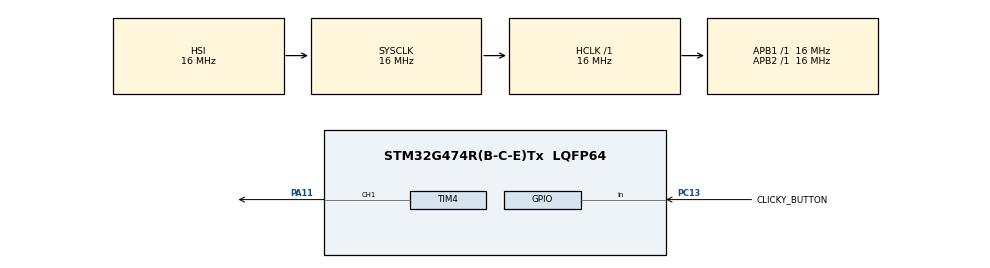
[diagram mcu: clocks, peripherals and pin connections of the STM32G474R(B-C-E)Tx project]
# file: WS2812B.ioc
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Dma.Request0=TIM4_CH1
Dma.TIM4_CH1.0.Direction=DMA_PERIPH_TO_MEMORY
Dma.TIM4_CH1.0.EventEnable=DISABLE
Dma.TIM4_CH1.0.Instance=DMA1_Channel1
Dma.TIM4_CH1.0.MemDataAlignment=DMA_MDATAALIGN_BYTE
Dma.TIM4_CH1.0.MemInc=DMA_MINC_ENABLE
Dma.TIM4_CH1.0.Mode=DMA_NORMAL
Dma.TIM4_CH1.0.PeriphDataAlignment=DMA_PDATAALIGN_HALFWORD
Dma.TIM4_CH1.0.PeriphInc=DMA_PINC_DISABLE
Dma.TIM4_CH1.0.Polarity=HAL_DMAMUX_REQ_GEN_RISING
Dma.TIM4_CH1.0.Priority=DMA_PRIORITY_LOW
Dma.TIM4_CH1.0.RequestNumber=1
Dma.TIM4_CH1.0.SignalID=NONE
Dma.TIM4_CH1.0.SyncEnable=DISABLE
Dma.TIM4_CH1.0.SyncPolarity=HAL_DMAMUX_SYNC_NO_EVENT
Dma.TIM4_CH1.0.SyncRequestNumber=1
Dma.TIM4_CH1.0.SyncSignalID=NONE
Mcu.Family=STM32G4
Mcu.Name=STM32G474R(B-C-E)Tx
Mcu.Package=LQFP64
NVIC.DMA1_Channel1_IRQn=true\:0\:0\:false\:false\:true\:false\:true\:true
NVIC.PriorityGroup=NVIC_PRIORITYGROUP_4
PA11.Signal=S_TIM4_CH1
PC13.GPIO_Label=CLICKY_BUTTON
PC13.Signal=GPIO_Input
ProjectManager.HeapSize=0x200
ProjectManager.StackSize=0x400
ProjectManager.TargetToolchain=STM32CubeIDE
RCC.AHBFreq_Value=16000000
RCC.APB1Freq_Value=16000000
RCC.APB1TimFreq_Value=16000000
RCC.APB2Freq_Value=16000000
RCC.APB2TimFreq_Value=16000000
RCC.CortexFreq_Value=16000000
RCC.EXTERNAL_CLOCK_VALUE=12288000
RCC.HCLKFreq_Value=16000000
RCC.HSE_VALUE=8000000
RCC.HSI48_VALUE=48000000
RCC.HSI_VALUE=16000000
RCC.LSE_VALUE=32768
RCC.SYSCLKFreq_VALUE=16000000
RCC.USBFreq_Value=64000000
RCC.VCOOutputFreq_Value=128000000
SH.S_TIM4_CH1.0=TIM4_CH1,PWM Generation1 CH1
TIM4.Channel-PWM\ Generation1\ CH1=TIM_CHANNEL_1
TIM4.PeriodNoDither=20
TIM4.Prescaler=0
TIM4.PulseNoDither_1=0
VP_SYS_VS_DBSignals.Mode=DisableDeadBatterySignals
board=custom

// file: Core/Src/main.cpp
/* USER CODE BEGIN Header */
/**
  ******************************************************************************
  * @file           : main.c
  * @brief          : Main program body
  ******************************************************************************
  * @attention
  *
  * Copyright (c) 2024 STMicroelectronics.
  * All rights reserved.
  *
  * This software is licensed under terms that can be found in the LICENSE file
  * in the root directory of this software component.
  * If no LICENSE file comes with this software, it is provided AS-IS.
  *
  ******************************************************************************
  */
/* USER CODE END Header */
#include "main.h"

/* USER CODE BEGIN Includes */
#include "WS2812B.hpp"

/* USER CODE END Includes */

TIM_HandleTypeDef htim4;
DMA_HandleTypeDef hdma_tim4_ch1;

void SystemClock_Config(void);
static void MX_GPIO_Init(void);
static void MX_DMA_Init(void);
static void MX_TIM4_Init(void);

/* USER CODE BEGIN 0 */
#define PERIOD_MS 3000
// Percentage of current period. 0% - 0, 100% - 255
uint8_t area = 0;
// Stores time to calculate percentage.
uint32_t last_time;
// 1 if button has been pressed and hasn't been cleared yet.
uint8_t clicked = 0;

/**
 * Checks if GPIO has been shorted.
 *
 * 255 is end of the period.
 * 0 is start of the period.
 * May miss timings when GPIO is pressed if full execution of main loop takes too long.
 * A better solution would be to use interrupts, but this simple example will do.
 */
#warning "Use interrupts instead if main loop runs too long to catch all presses"
void update_click(GPIO_TypeDef *GPIOx, uint16_t GPIO_Pin){
	if(HAL_GPIO_ReadPin(GPIOx, GPIO_Pin)) clicked = 1;
	else clicked = 0;
}

/**
 * Updates the percentage of the current period.
 *
 * 255 is end of the period.
 * 0 is start of the period.
 */
void update_area(){
	uint32_t current_time = HAL_GetTick();
	if(current_time - last_time >= PERIOD_MS){
		last_time=current_time;
		area = 0;
	}
	// I know it will be only approximation and for small values of delta T it will be shown as 0 but it's good enough
	area = ((current_time-last_time)*255)/PERIOD_MS;
}

/**
 * Modulation of the green part of the LED.
 *
 * Generates a pulse with a sawtooth signal.
 */
uint8_t greenStep(uint8_t area){
	return area;
}

/**
 * Modulation of the red part of the LED.
 *
 * Generates a pulse with a width of 1/2 the period.
 */
uint8_t redStep(uint8_t area){
	if(area < 128) return 255;
	return 0;
}

/**
 * Modulation of the blue part of the LED.
 *
 * Blinks 3 in the period after registering clicked GPIO.
 */
uint8_t blueStep(uint8_t area, uint8_t clicked){
	if(!clicked) return 0;

	// some approximation, because it doesn't have to be that precise
	else{
		if(((area - (area % 42))/43) & 1) return 255;
	}
	return 0;
}

/**
 * LED modulation function.
 *
 * Modulates LEDs in the strip to output the correct signals.
 */
int modulation(LED* led, const int i, const int feedback){
	led->blue = blueStep(area, clicked);
	led->red = redStep(area);
	led->red = redStep(area);
	return 0;
}

/**
 * PWM completion callback.
 *
 * Called after the PWM function has been executed, tells PWM to stop before the next batch of data.
 */
void HAL_TIM_PWM_PulseFinishedCallback(TIM_HandleTypeDef *htim)
{
	if(TIM4 == htim->Instance)
	{
		HAL_TIM_PWM_Stop(&htim4, TIM_CHANNEL_1);
	}
}

/* USER CODE END 0 */

int main(void)
{

  /* MCU Configuration--------------------------------------------------------*/

  /* Reset of all peripherals, Initializes the Flash interface and the Systick. */
  HAL_Init();

  /* Configure the system clock */
  SystemClock_Config();

  /* Initialize all configured peripherals */
  MX_GPIO_Init();
  MX_DMA_Init();
  MX_TIM4_Init();
  /* USER CODE BEGIN 2 */
  // Set start time to ensure there is no garbage in the variable.
  last_time = HAL_GetTick();
  // Set starting percentage to 0
  area = 0;
  // Initialise the strip with the length of the 10 (10 LEDs).
  Strip<10>	strip(&htim4, TIM_CHANNEL_1);
  // Set callback for LED.
  strip.setLedCallback(modulation);
  /* USER CODE END 2 */

  /* Infinite loop */
  /* USER CODE BEGIN WHILE */
  while (1)
  {
	// Check for presses.
	update_click(CLICKY_BUTTON_GPIO_Port, CLICKY_BUTTON_Pin);
	// Update period.
	update_area();
	// Run strip
    strip.run();
    /* USER CODE END WHILE */

  }
}

void SystemClock_Config(void)
{
  RCC_OscInitTypeDef RCC_OscInitStruct = {0};
  RCC_ClkInitTypeDef RCC_ClkInitStruct = {0};

  /** Configure the main internal regulator output voltage
  */
  HAL_PWREx_ControlVoltageScaling(PWR_REGULATOR_VOLTAGE_SCALE1);

  /** Initializes the RCC Oscillators according to the specified parameters
  * in the RCC_OscInitTypeDef structure.
  */
  RCC_OscInitStruct.OscillatorType = RCC_OSCILLATORTYPE_HSI;
  RCC_OscInitStruct.HSIState = RCC_HSI_ON;
  RCC_OscInitStruct.HSICalibrationValue = RCC_HSICALIBRATION_DEFAULT;
  RCC_OscInitStruct.PLL.PLLState = RCC_PLL_NONE;
  if (HAL_RCC_OscConfig(&RCC_OscInitStruct) != HAL_OK)
  {
    Error_Handler();
  }

  /** Initializes the CPU, AHB and APB buses clocks
  */
  RCC_ClkInitStruct.ClockType = RCC_CLOCKTYPE_HCLK|RCC_CLOCKTYPE_SYSCLK
                              |RCC_CLOCKTYPE_PCLK1|RCC_CLOCKTYPE_PCLK2;
  RCC_ClkInitStruct.SYSCLKSource = RCC_SYSCLKSOURCE_HSI;
  RCC_ClkInitStruct.AHBCLKDivider = RCC_SYSCLK_DIV1;
  RCC_ClkInitStruct.APB1CLKDivider = RCC_HCLK_DIV1;
  RCC_ClkInitStruct.APB2CLKDivider = RCC_HCLK_DIV1;

  if (HAL_RCC_ClockConfig(&RCC_ClkInitStruct, FLASH_LATENCY_0) != HAL_OK)
  {
    Error_Handler();
  }
}

static void MX_TIM4_Init(void)
{

  TIM_MasterConfigTypeDef sMasterConfig = {0};
  TIM_OC_InitTypeDef sConfigOC = {0};

  htim4.Instance = TIM4;
  htim4.Init.Prescaler = 0;
  htim4.Init.CounterMode = TIM_COUNTERMODE_UP;
  htim4.Init.Period = 20;
  htim4.Init.ClockDivision = TIM_CLOCKDIVISION_DIV1;
  htim4.Init.AutoReloadPreload = TIM_AUTORELOAD_PRELOAD_DISABLE;
  if (HAL_TIM_PWM_Init(&htim4) != HAL_OK)
  {
    Error_Handler();
  }
  sMasterConfig.MasterOutputTrigger = TIM_TRGO_RESET;
  sMasterConfig.MasterSlaveMode = TIM_MASTERSLAVEMODE_DISABLE;
  if (HAL_TIMEx_MasterConfigSynchronization(&htim4, &sMasterConfig) != HAL_OK)
  {
    Error_Handler();
  }
  sConfigOC.OCMode = TIM_OCMODE_PWM1;
  sConfigOC.Pulse = 0;
  sConfigOC.OCPolarity = TIM_OCPOLARITY_HIGH;
  sConfigOC.OCFastMode = TIM_OCFAST_DISABLE;
  if (HAL_TIM_PWM_ConfigChannel(&htim4, &sConfigOC, TIM_CHANNEL_1) != HAL_OK)
  {
    Error_Handler();
  }
  HAL_TIM_MspPostInit(&htim4);

}

static void MX_DMA_Init(void)
{

  /* DMA controller clock enable */
  __HAL_RCC_DMAMUX1_CLK_ENABLE();
  __HAL_RCC_DMA1_CLK_ENABLE();

  /* DMA interrupt init */
  /* DMA1_Channel1_IRQn interrupt configuration */
  HAL_NVIC_SetPriority(DMA1_Channel1_IRQn, 0, 0);
  HAL_NVIC_EnableIRQ(DMA1_Channel1_IRQn);

}

static void MX_GPIO_Init(void)
{
  GPIO_InitTypeDef GPIO_InitStruct = {0};

  /* GPIO Ports Clock Enable */
  __HAL_RCC_GPIOC_CLK_ENABLE();
  __HAL_RCC_GPIOA_CLK_ENABLE();

  /*Configure GPIO pin : CLICKY_BUTTON_Pin */
  GPIO_InitStruct.Pin = CLICKY_BUTTON_Pin;
  GPIO_InitStruct.Mode = GPIO_MODE_INPUT;
  GPIO_InitStruct.Pull = GPIO_NOPULL;
  HAL_GPIO_Init(CLICKY_BUTTON_GPIO_Port, &GPIO_InitStruct);

}

void Error_Handler(void)
{
  __disable_irq();
  while (1)
  {
  }
}
